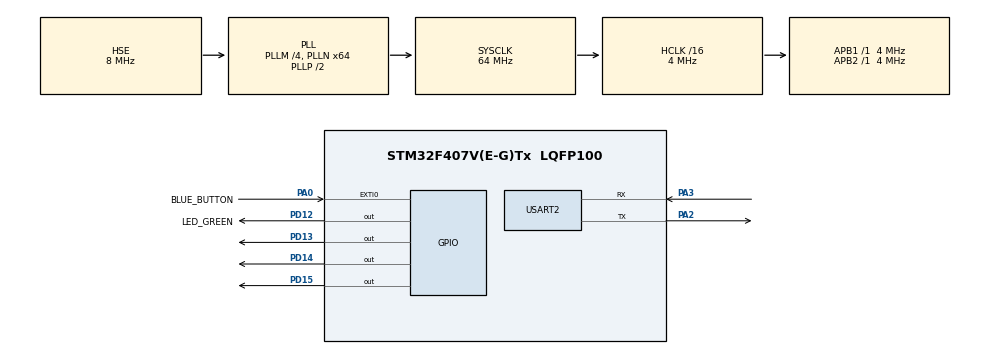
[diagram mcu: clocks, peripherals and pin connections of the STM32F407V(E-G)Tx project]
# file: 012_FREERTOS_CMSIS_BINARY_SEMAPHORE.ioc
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FREERTOS.BinarySemaphores01=myBinarySem01,Dynamic,NULL
FREERTOS.Tasks01=Task1,24,256,StartTask1,Default,NULL,Dynamic,NULL,NULL;Task2,24,256,StartTask2,Default,NULL,Dynamic,NULL,NULL
FREERTOS.configUSE_NEWLIB_REENTRANT=1
Mcu.Family=STM32F4
Mcu.Name=STM32F407V(E-G)Tx
Mcu.Package=LQFP100
NVIC.EXTI0_IRQn=true\:5\:0\:false\:false\:true\:true\:true\:true\:true
NVIC.PriorityGroup=NVIC_PRIORITYGROUP_4
NVIC.TIM8_TRG_COM_TIM14_IRQn=true\:15\:0\:false\:false\:true\:false\:false\:true\:true
NVIC.TimeBase=TIM8_TRG_COM_TIM14_IRQn
NVIC.TimeBaseIP=TIM14
NVIC.USART2_IRQn=true\:5\:0\:false\:false\:true\:true\:true\:true\:true
PA0-WKUP.GPIO_Label=BLUE_BUTTON
PA0-WKUP.Signal=GPXTI0
PA13.Mode=Trace_Asynchronous_SW
PA13.Signal=SYS_JTMS-SWDIO
PA14.Mode=Trace_Asynchronous_SW
PA14.Signal=SYS_JTCK-SWCLK
PA2.Mode=Asynchronous
PA2.Signal=USART2_TX
PA3.Mode=Asynchronous
PA3.Signal=USART2_RX
PB3.Mode=Trace_Asynchronous_SW
PB3.Signal=SYS_JTDO-SWO
PD12.GPIO_Label=LED_GREEN
PD12.Signal=GPIO_Output
PD13.Signal=GPIO_Output
PD14.Signal=GPIO_Output
PD15.Signal=GPIO_Output
PH0-OSC_IN.Mode=HSE-External-Oscillator
PH0-OSC_IN.Signal=RCC_OSC_IN
PH1-OSC_OUT.Mode=HSE-External-Oscillator
PH1-OSC_OUT.Signal=RCC_OSC_OUT
ProjectManager.HeapSize=0x200
ProjectManager.StackSize=0x400
ProjectManager.TargetToolchain=STM32CubeIDE
RCC.48MHZClocksFreq_Value=18285714.285714287
RCC.AHBCLKDivider=RCC_SYSCLK_DIV16
RCC.AHBFreq_Value=4000000
RCC.APB1Freq_Value=4000000
RCC.APB1TimFreq_Value=4000000
RCC.APB2Freq_Value=4000000
RCC.APB2TimFreq_Value=4000000
RCC.CortexFreq_Value=4000000
RCC.HCLKFreq_Value=4000000
RCC.HSE_VALUE=8000000
RCC.HSI_VALUE=16000000
RCC.LSE_VALUE=32768
RCC.PLLM=4
RCC.PLLN=64
RCC.PLLQ=7
RCC.PLLSourceVirtual=RCC_PLLSOURCE_HSE
RCC.SYSCLKFreq_VALUE=64000000
RCC.SYSCLKSource=RCC_SYSCLKSOURCE_PLLCLK
RCC.VCOOutputFreq_Value=128000000
USART2.VirtualMode=VM_ASYNC
VP_FREERTOS_VS_CMSIS_V2.Mode=CMSIS_V2
VP_SYS_VS_tim14.Mode=TIM14
board=STM32F407G-DISC1

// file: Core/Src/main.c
/* USER CODE BEGIN Header */
/**
  ******************************************************************************
  * @file           : main.c
  * @brief          : Main program body
  ******************************************************************************
  * @attention
  *
  * Copyright (c) 2023 STMicroelectronics.
  * All rights reserved.
  *
  * This software is licensed under terms that can be found in the LICENSE file
  * in the root directory of this software component.
  * If no LICENSE file comes with this software, it is provided AS-IS.
  *
  ******************************************************************************
  */
/* USER CODE END Header */
#include "main.h"
#include "cmsis_os.h"

UART_HandleTypeDef huart2;

/* Definitions for Task1 */
osThreadId_t Task1Handle;
const osThreadAttr_t Task1_attributes = {
  .name = "Task1",
  .stack_size = 256 * 4,
  .priority = (osPriority_t) osPriorityNormal,
};
/* Definitions for Task2 */
osThreadId_t Task2Handle;
const osThreadAttr_t Task2_attributes = {
  .name = "Task2",
  .stack_size = 256 * 4,
  .priority = (osPriority_t) osPriorityNormal,
};
/* Definitions for myBinarySem01 */
osSemaphoreId_t myBinarySem01Handle;
const osSemaphoreAttr_t myBinarySem01_attributes = {
  .name = "myBinarySem01"
};

void SystemClock_Config(void);
static void MX_GPIO_Init(void);
static void MX_USART2_UART_Init(void);
void StartTask1(void *argument);
void StartTask2(void *argument);

int main(void)
{

  /* MCU Configuration--------------------------------------------------------*/

  /* Reset of all peripherals, Initializes the Flash interface and the Systick. */
  HAL_Init();

  /* Configure the system clock */
  SystemClock_Config();

  /* Initialize all configured peripherals */
  MX_GPIO_Init();
  MX_USART2_UART_Init();

  /* Init scheduler */
  osKernelInitialize();

  /* Create the semaphores(s) */
  /* creation of myBinarySem01 */
  myBinarySem01Handle = osSemaphoreNew(1, 0, &myBinarySem01_attributes);

  /* Create the thread(s) */
  /* creation of Task1 */
  Task1Handle = osThreadNew(StartTask1, NULL, &Task1_attributes);

  /* creation of Task2 */
  Task2Handle = osThreadNew(StartTask2, NULL, &Task2_attributes);

  /* Start scheduler */
  osKernelStart();
  /* We should never get here as control is now taken by the scheduler */
  /* Infinite loop */
  while (1)
  {

  }
}

void SystemClock_Config(void)
{
  RCC_OscInitTypeDef RCC_OscInitStruct = {0};
  RCC_ClkInitTypeDef RCC_ClkInitStruct = {0};

  /** Configure the main internal regulator output voltage
  */
  __HAL_RCC_PWR_CLK_ENABLE();
  __HAL_PWR_VOLTAGESCALING_CONFIG(PWR_REGULATOR_VOLTAGE_SCALE1);

  /** Initializes the RCC Oscillators according to the specified parameters
  * in the RCC_OscInitTypeDef structure.
  */
  RCC_OscInitStruct.OscillatorType = RCC_OSCILLATORTYPE_HSE;
  RCC_OscInitStruct.HSEState = RCC_HSE_ON;
  RCC_OscInitStruct.PLL.PLLState = RCC_PLL_ON;
  RCC_OscInitStruct.PLL.PLLSource = RCC_PLLSOURCE_HSE;
  RCC_OscInitStruct.PLL.PLLM = 4;
  RCC_OscInitStruct.PLL.PLLN = 64;
  RCC_OscInitStruct.PLL.PLLP = RCC_PLLP_DIV2;
  RCC_OscInitStruct.PLL.PLLQ = 7;
  if (HAL_RCC_OscConfig(&RCC_OscInitStruct) != HAL_OK)
  {
    Error_Handler();
  }

  /** Initializes the CPU, AHB and APB buses clocks
  */
  RCC_ClkInitStruct.ClockType = RCC_CLOCKTYPE_HCLK|RCC_CLOCKTYPE_SYSCLK
                              |RCC_CLOCKTYPE_PCLK1|RCC_CLOCKTYPE_PCLK2;
  RCC_ClkInitStruct.SYSCLKSource = RCC_SYSCLKSOURCE_PLLCLK;
  RCC_ClkInitStruct.AHBCLKDivider = RCC_SYSCLK_DIV16;
  RCC_ClkInitStruct.APB1CLKDivider = RCC_HCLK_DIV1;
  RCC_ClkInitStruct.APB2CLKDivider = RCC_HCLK_DIV1;

  if (HAL_RCC_ClockConfig(&RCC_ClkInitStruct, FLASH_LATENCY_0) != HAL_OK)
  {
    Error_Handler();
  }
}

static void MX_USART2_UART_Init(void)
{

  huart2.Instance = USART2;
  huart2.Init.BaudRate = 115200;
  huart2.Init.WordLength = UART_WORDLENGTH_8B;
  huart2.Init.StopBits = UART_STOPBITS_1;
  huart2.Init.Parity = UART_PARITY_NONE;
  huart2.Init.Mode = UART_MODE_TX_RX;
  huart2.Init.HwFlowCtl = UART_HWCONTROL_NONE;
  huart2.Init.OverSampling = UART_OVERSAMPLING_16;
  if (HAL_UART_Init(&huart2) != HAL_OK)
  {
    Error_Handler();
  }

}

static void MX_GPIO_Init(void)
{
  GPIO_InitTypeDef GPIO_InitStruct = {0};

  /* GPIO Ports Clock Enable */
  __HAL_RCC_GPIOH_CLK_ENABLE();
  __HAL_RCC_GPIOA_CLK_ENABLE();
  __HAL_RCC_GPIOD_CLK_ENABLE();
  __HAL_RCC_GPIOB_CLK_ENABLE();

  /*Configure GPIO pin Output Level */
  HAL_GPIO_WritePin(GPIOD, LED_GREEN_Pin|GPIO_PIN_13|GPIO_PIN_14|GPIO_PIN_15, GPIO_PIN_RESET);

  /*Configure GPIO pin : BLUE_BUTTON_Pin */
  GPIO_InitStruct.Pin = BLUE_BUTTON_Pin;
  GPIO_InitStruct.Mode = GPIO_MODE_IT_RISING;
  GPIO_InitStruct.Pull = GPIO_NOPULL;
  HAL_GPIO_Init(BLUE_BUTTON_GPIO_Port, &GPIO_InitStruct);

  /*Configure GPIO pins : LED_GREEN_Pin PD13 PD14 PD15 */
  GPIO_InitStruct.Pin = LED_GREEN_Pin|GPIO_PIN_13|GPIO_PIN_14|GPIO_PIN_15;
  GPIO_InitStruct.Mode = GPIO_MODE_OUTPUT_PP;
  GPIO_InitStruct.Pull = GPIO_NOPULL;
  GPIO_InitStruct.Speed = GPIO_SPEED_FREQ_LOW;
  HAL_GPIO_Init(GPIOD, &GPIO_InitStruct);

  /* EXTI interrupt init*/
  HAL_NVIC_SetPriority(EXTI0_IRQn, 5, 0);
  HAL_NVIC_EnableIRQ(EXTI0_IRQn);

}

/* USER CODE BEGIN 4 */
void Task_action(char message)
{
	ITM_SendChar(message);
	ITM_SendChar('\n');
}
/* USER CODE END 4 */

void StartTask1(void *argument)
{
  /* USER CODE BEGIN 5 */
  /* Infinite loop */
  for(;;)
  {
    osDelay(2000);
    Task_action('1');
    osSemaphoreRelease(myBinarySem01Handle);
  }
  /* USER CODE END 5 */
}

void StartTask2(void *argument)
{
  /* USER CODE BEGIN StartTask2 */
  /* Infinite loop */
  for(;;)
  {
	osSemaphoreAcquire(myBinarySem01Handle, 4000);
    Task_action('2');
  }
  /* USER CODE END StartTask2 */
}

void HAL_TIM_PeriodElapsedCallback(TIM_HandleTypeDef *htim)
{
  if (htim->Instance == TIM14) {
    HAL_IncTick();
  }
}

void Error_Handler(void)
{
  __disable_irq();
  while (1)
  {
  }
}
